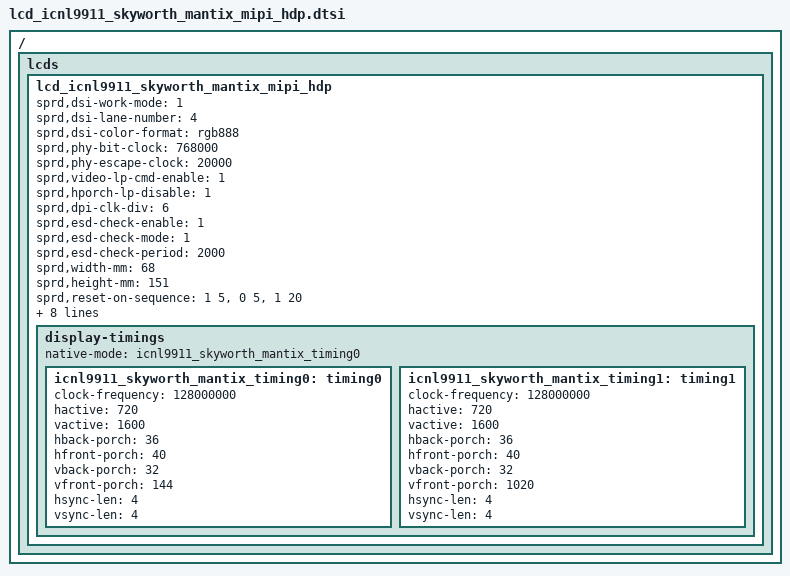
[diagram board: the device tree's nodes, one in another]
/*
 * icnl9911 skyworth LCD config dtsi file for spreadtrum
 *
 * Copyright (C) 2018, Spreadtrum Communications Inc.
 *
 * SPDX-License-Identifier: (GPL-2.0+ OR MIT)
 */

/ {
	fragment {
		target-path = "/";
		__overlay__ {
			lcds {
				lcd_icnl9911_skyworth_mantix_mipi_hdp: lcd_icnl9911_skyworth_mantix_mipi_hdp {

					sprd,dsi-work-mode = <1>; /* video burst mode*/
//					sprd,dsi-work-mode = <3>; /* video SPRD_DSI_MODE_VIDEO_SYNC_EVENT mode*/
					sprd,dsi-lane-number = <4>;
					sprd,dsi-color-format = "rgb888";


					sprd,phy-bit-clock = <768000>;	/* kbps */
					sprd,phy-escape-clock = <20000>;/* kHz */
					sprd,video-lp-cmd-enable = <1>;
					sprd,hporch-lp-disable = <1>;
					sprd,dpi-clk-div = <6>;
//Modify by pengzhenhua1@wingtech.com for SCT-702,wt add esd te mode(2021.10.25) begin
					sprd,esd-check-enable = <1>;
					sprd,esd-check-mode = <1>;
					sprd,esd-check-period = <2000>;
//Modify by pengzhenhua1@wingtech.com for SCT-702,wt add esd te mode(2021.10.25) end				
					sprd,width-mm = <68>;
					sprd,height-mm = <151>;
					
					sprd,reset-on-sequence = <1 5>, <0 5>, <1 20>;
					sprd,reset-off-sequence = <1 5>;

					sprd,use-dcs-write;

					sprd,initial-command = [
						39 00 00 03 F0 5A 59
						39 00 00 03 F1 A5 A6
						39 00 00 1F B0 82 81 05 04 87 86 84 85 66 66 33 33 20 00 00 78 00 00 0F 05 04 03 02 01 02 03 04 00 00 00
						39 00 00 1E B1 13 42 86 00 00 05 05 54 05 00 04 08 54 00 00 00 44 40 02 01 40 02 01 40 02 01 40 02 01
						39 00 00 12 B2 54 C4 82 05 40 02 01 40 02 01 05 05 54 0C 0C 0D 0B
						39 00 00 20 B3 02 00 00 00 00 26 26 91 A2 33 44 00 26 00 18 01 02 08 20 30 08 09 44 20 40 20 40 08 09 22 33
						// FORWORD SCAN
						39 00 00 1D B4 0A 02 DC 1D 00 02 02 02 02 12 10 02 02 0E 0C 04 03 03 03 03 03 03 FF FF FC 00 00 00
						39 00 00 1D B5 0B 02 DC 1D 00 02 02 02 02 13 11 02 02 0F 0D 05 03 03 03 03 03 03 FF FF FC 00 00 00
						// BACKWORD SCAN
						//15 00 00 02 36 03
						//39 00 00 1D B4 05 02 1C DD 00 02 02 02 02 0D 0F 02 02 11 13 0B 03 03 03 03 03 03 FF FF FC 00 00 00
						//39 00 00 1D B5 04 02 1C DD 00 02 02 02 02 0C 0E 02 02 10 12 0A 03 03 03 03 03 03 FF FF FC 00 00 00
						39 00 00 19 B8 00 00 00 00 00 00 00 00 00 00 00 00 00 00 00 00 00 00 00 00 00 00 00 00
						39 00 00 0E BB 01 05 09 11 0D 19 1D 55 25 69 00 21 25
						39 00 00 0F BC 00 00 00 00 02 20 FF 00 03 33 01 73 33 00
						39 00 00 0B BD E9 02 4E CF 72 A4 08 44 AE 15
						39 00 00 0B BE 72 72 50 46 0C 77 43 07 0E 0E
						39 00 00 09 BF 07 25 07 25 7F 00 11 04
						39 00 00 0A C0 10 FF FF FF FF FF 00 FF 00
						39 00 00 14 C1 C0 20 20 96 04 20 28 04 2A 40 36 00 07 CF FF FF 7C 01 C0
						39 00 00 0A C2 CC 01 10 00 01 30 02 21 43
						39 00 00 0A C3 06 00 FF 00 FF 00 00 81 01
						39 00 00 0B C4 84 01 2B 41 00 3C 00 03 03 2E
						39 00 00 0C C5 03 1C C0 C0 40 10 42 44 08 09 14
						39 00 00 0B C6 87 96 2A 29 29 33 7F 34 08 04//H-LINETUNING
						//GAMMA2.2
						39 00 00 17 C7 FC 8B 60 43 13 F4 C8 21 F4 D2 AF 87 E4 BC A1 7B 64 45 1A 7C 80 00
						39 00 00 17 C8 FC 8B 60 43 13 F4 C8 21 F4 D2 AF 87 E4 BC A1 7B 64 45 1A 7C 80 00
						15 00 00 02 CB 00
						39 00 00 06 D0 80 0D FF 0F 61
						15 00 00 02 D2 42
						39 00 00 04 FA 45 93 01
						39 00 00 05 FE FF FF FF 50//OSCMARK80M
						39 00 00 03 F1 5A 59
						39 00 00 03 F0 A5 A6
						15 00 00 02 35 00

						23 78 00 02 11 00
						23 14 00 02 29 00
						23 00 00 02 26 02
						];

					sprd,sleep-in-command = [
						23 00 00 02 26 08
						23 23 00 02 28 00
						23 78 00 02 10 00
						];

					sprd,sleep-out-command = [
						23 78 00 02 11 00
						23 23 00 02 29 00
						23 00 00 02 26 02
						];

					display-timings {
						native-mode = <&icnl9911_skyworth_mantix_timing0>;

						icnl9911_skyworth_mantix_timing0: timing0 {
							clock-frequency = <128000000>;
							hactive = <720>;
							vactive = <1600>;
							hback-porch = <36>;	//Modify by pengzhenhua1@wingtech.com for SCP-2332,wt Modify 60 fps lcd timing (2021.11.24)
							hfront-porch = <40>;
							vback-porch = <32>;	//Modify by pengzhenhua1@wingtech.com for SCP-2332,wt Modify 60 fps lcd timing (2021.11.24)
							vfront-porch = <144>;	//Modify by pengzhenhua1@wingtech.com for SCP-2332,wt Modify 60 fps lcd timing (2021.11.24)
							hsync-len = <4>;
							vsync-len = <4>;
						};
						icnl9911_skyworth_mantix_timing1: timing1 {
							clock-frequency = <128000000>;
							hactive = <720>;
							vactive = <1600>;
							hback-porch = <36>;	//Modify by pengzhenhua1@wingtech.com for SCP-2332,wt Modify 60 fps lcd timing (2021.11.24)
							hfront-porch = <40>;
							vback-porch = <32>;	//Modify by pengzhenhua1@wingtech.com for SCP-2332,wt Modify 60 fps lcd timing (2021.11.24)
							vfront-porch = <1020>;
							hsync-len = <4>;
							vsync-len = <4>;
						};
					};
				};
			};
		};
	};
};
